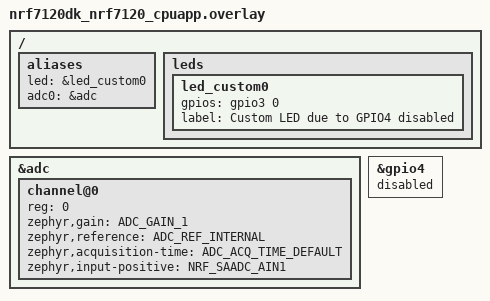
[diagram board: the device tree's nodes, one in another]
/ {
	aliases {
		led = &led_custom0;
		adc0 = &adc;
	};

	leds {
		led_custom0: led_custom0 {
			gpios = <&gpio3 0 GPIO_ACTIVE_HIGH>;
			label = "Custom LED due to GPIO4 disabled";
		};
	};
};

&adc {
	#address-cells = <1>;
	#size-cells = <0>;

	channel@0 {
		reg = <0>;
		zephyr,gain = "ADC_GAIN_1";
		zephyr,reference = "ADC_REF_INTERNAL";
		zephyr,acquisition-time = <ADC_ACQ_TIME_DEFAULT>;
		zephyr,input-positive = <NRF_SAADC_AIN1>;
	};
};

&gpio4 {
	status = "disabled";
};
